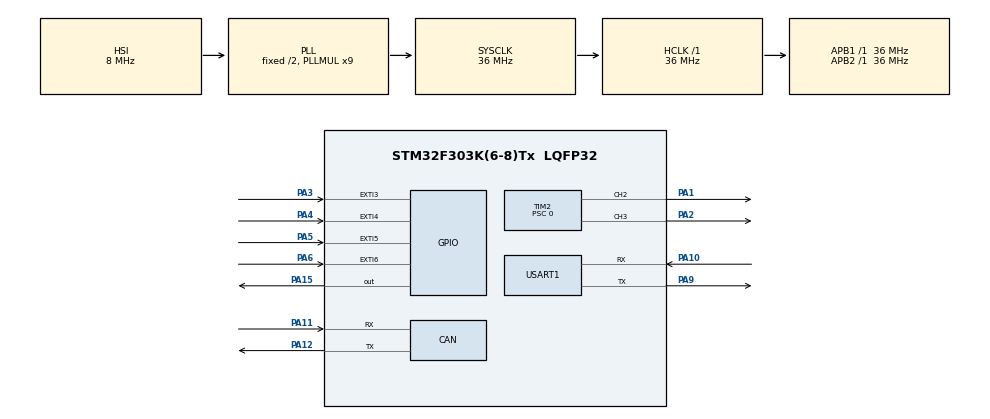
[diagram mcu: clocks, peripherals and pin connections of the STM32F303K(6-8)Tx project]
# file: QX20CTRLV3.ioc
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CAN.CalculateTimeQuantum=444.44444444444446
Dma.Request0=USART1_RX
Dma.Request1=USART1_TX
Dma.USART1_RX.0.Direction=DMA_PERIPH_TO_MEMORY
Dma.USART1_RX.0.Instance=DMA1_Channel5
Dma.USART1_RX.0.MemDataAlignment=DMA_MDATAALIGN_BYTE
Dma.USART1_RX.0.MemInc=DMA_MINC_ENABLE
Dma.USART1_RX.0.Mode=DMA_CIRCULAR
Dma.USART1_RX.0.PeriphDataAlignment=DMA_PDATAALIGN_BYTE
Dma.USART1_RX.0.PeriphInc=DMA_PINC_DISABLE
Dma.USART1_RX.0.Priority=DMA_PRIORITY_LOW
Dma.USART1_TX.1.Direction=DMA_MEMORY_TO_PERIPH
Dma.USART1_TX.1.Instance=DMA1_Channel4
Dma.USART1_TX.1.MemDataAlignment=DMA_MDATAALIGN_BYTE
Dma.USART1_TX.1.MemInc=DMA_MINC_ENABLE
Dma.USART1_TX.1.Mode=DMA_NORMAL
Dma.USART1_TX.1.PeriphDataAlignment=DMA_PDATAALIGN_BYTE
Dma.USART1_TX.1.PeriphInc=DMA_PINC_DISABLE
Dma.USART1_TX.1.Priority=DMA_PRIORITY_LOW
Mcu.Family=STM32F3
Mcu.Name=STM32F303K(6-8)Tx
Mcu.Package=LQFP32
NVIC.DMA1_Channel4_IRQn=true\:0\:0\:false\:false\:true\:false\:true
NVIC.DMA1_Channel5_IRQn=true\:0\:0\:false\:false\:true\:false\:true
NVIC.EXTI3_IRQn=true\:0\:0\:false\:false\:true\:true\:true
NVIC.EXTI4_IRQn=true\:0\:0\:false\:false\:true\:true\:true
NVIC.EXTI9_5_IRQn=true\:0\:0\:false\:false\:true\:true\:true
NVIC.PriorityGroup=NVIC_PRIORITYGROUP_4
PA1.Signal=S_TIM2_CH2
PA10.Mode=Asynchronous
PA10.Signal=USART1_RX
PA11.Mode=Master
PA11.Signal=CAN_RX
PA12.Mode=Master
PA12.Signal=CAN_TX
PA15.Signal=GPIO_Output
PA2.Signal=S_TIM2_CH3
PA3.GPIO_ModeDefaultEXTI=GPIO_MODE_IT_RISING_FALLING
PA3.GPIO_PuPd=GPIO_PULLUP
PA3.Signal=GPXTI3
PA4.GPIO_ModeDefaultEXTI=GPIO_MODE_IT_RISING_FALLING
PA4.GPIO_PuPd=GPIO_PULLUP
PA4.Signal=GPXTI4
PA5.GPIO_ModeDefaultEXTI=GPIO_MODE_IT_RISING_FALLING
PA5.GPIO_PuPd=GPIO_PULLUP
PA5.Signal=GPXTI5
PA6.GPIO_ModeDefaultEXTI=GPIO_MODE_IT_RISING_FALLING
PA6.GPIO_PuPd=GPIO_PULLUP
PA6.Signal=GPXTI6
PA9.Mode=Asynchronous
PA9.Signal=USART1_TX
ProjectManager.HeapSize=0x200
ProjectManager.StackSize=0x400
ProjectManager.TargetToolchain=Makefile
RCC.AHBFreq_Value=36000000
RCC.APB1Freq_Value=36000000
RCC.APB1TimFreq_Value=36000000
RCC.APB2Freq_Value=36000000
RCC.APB2TimFreq_Value=36000000
RCC.CortexFreq_Value=36000000
RCC.HCLKFreq_Value=36000000
RCC.HSE_VALUE=8000000
RCC.HSI_VALUE=8000000
RCC.PLLMUL=RCC_PLL_MUL9
RCC.SYSCLKFreq_VALUE=36000000
RCC.SYSCLKSourceVirtual=RCC_SYSCLKSOURCE_PLLCLK
SH.S_TIM2_CH2.0=TIM2_CH2,PWM Generation2 CH2
SH.S_TIM2_CH3.0=TIM2_CH3,PWM Generation3 CH3
TIM2.Channel-PWM\ Generation2\ CH2=TIM_CHANNEL_2
TIM2.Channel-PWM\ Generation3\ CH3=TIM_CHANNEL_3
TIM2.Period=720000
TIM2.Prescaler=0
TIM2.Pulse-PWM\ Generation2\ CH2=54000
TIM2.Pulse-PWM\ Generation3\ CH3=54000
USART1.VirtualMode-Asynchronous=VM_ASYNC
board=custom

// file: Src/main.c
/* USER CODE BEGIN Header */
/**
  ******************************************************************************
  * @file           : main.c
  * @brief          : Main program body
  ******************************************************************************
  * @attention
  *
  * <h2><center>&copy; Copyright (c) 2020 STMicroelectronics.
  * All rights reserved.</center></h2>
  *
  * This software component is licensed by ST under BSD 3-Clause license,
  * the "License"; You may not use this file except in compliance with the
  * License. You may obtain a copy of the License at:
  *                        opensource.org/licenses/BSD-3-Clause
  *
  ******************************************************************************
  */
/* USER CODE END Header */

#include "main.h"

/* USER CODE BEGIN Includes */
#include "qx20.h"
/* USER CODE END Includes */

CAN_HandleTypeDef hcan;

TIM_HandleTypeDef htim2;

UART_HandleTypeDef huart1;
DMA_HandleTypeDef hdma_usart1_rx;
DMA_HandleTypeDef hdma_usart1_tx;

void SystemClock_Config(void);
static void MX_GPIO_Init(void);
static void MX_DMA_Init(void);
static void MX_CAN_Init(void);
static void MX_TIM2_Init(void);
static void MX_USART1_UART_Init(void);

int main(void)
{

  /* MCU Configuration--------------------------------------------------------*/

  /* Reset of all peripherals, Initializes the Flash interface and the Systick. */
  HAL_Init();

  /* Configure the system clock */
  SystemClock_Config();

  /* Initialize all configured peripherals */
  MX_GPIO_Init();
  MX_DMA_Init();
  MX_CAN_Init();
  MX_TIM2_Init();
  MX_USART1_UART_Init();
  /* USER CODE BEGIN 2 */
	HAL_TIM_PWM_Start(&htim2, TIM_CHANNEL_2);
  HAL_TIM_PWM_Start(&htim2, TIM_CHANNEL_3);

  USART1_Init(&huart1);
  /* USER CODE END 2 */

  /* Infinite loop */
  while (1)
  {

  }
}

void SystemClock_Config(void)
{
  RCC_OscInitTypeDef RCC_OscInitStruct = {0};
  RCC_ClkInitTypeDef RCC_ClkInitStruct = {0};
  RCC_PeriphCLKInitTypeDef PeriphClkInit = {0};

  /** Initializes the CPU, AHB and APB busses clocks
  */
  RCC_OscInitStruct.OscillatorType = RCC_OSCILLATORTYPE_HSI;
  RCC_OscInitStruct.HSIState = RCC_HSI_ON;
  RCC_OscInitStruct.HSICalibrationValue = RCC_HSICALIBRATION_DEFAULT;
  RCC_OscInitStruct.PLL.PLLState = RCC_PLL_ON;
  RCC_OscInitStruct.PLL.PLLSource = RCC_PLLSOURCE_HSI;
  RCC_OscInitStruct.PLL.PLLMUL = RCC_PLL_MUL9;
  if (HAL_RCC_OscConfig(&RCC_OscInitStruct) != HAL_OK)
  {
    Error_Handler();
  }
  /** Initializes the CPU, AHB and APB busses clocks
  */
  RCC_ClkInitStruct.ClockType = RCC_CLOCKTYPE_HCLK|RCC_CLOCKTYPE_SYSCLK
                              |RCC_CLOCKTYPE_PCLK1|RCC_CLOCKTYPE_PCLK2;
  RCC_ClkInitStruct.SYSCLKSource = RCC_SYSCLKSOURCE_PLLCLK;
  RCC_ClkInitStruct.AHBCLKDivider = RCC_SYSCLK_DIV1;
  RCC_ClkInitStruct.APB1CLKDivider = RCC_HCLK_DIV1;
  RCC_ClkInitStruct.APB2CLKDivider = RCC_HCLK_DIV1;

  if (HAL_RCC_ClockConfig(&RCC_ClkInitStruct, FLASH_LATENCY_1) != HAL_OK)
  {
    Error_Handler();
  }
  PeriphClkInit.PeriphClockSelection = RCC_PERIPHCLK_USART1;
  PeriphClkInit.Usart1ClockSelection = RCC_USART1CLKSOURCE_PCLK1;
  if (HAL_RCCEx_PeriphCLKConfig(&PeriphClkInit) != HAL_OK)
  {
    Error_Handler();
  }
}

static void MX_CAN_Init(void)
{

  hcan.Instance = CAN;
  hcan.Init.Prescaler = 16;
  hcan.Init.Mode = CAN_MODE_NORMAL;
  hcan.Init.SyncJumpWidth = CAN_SJW_1TQ;
  hcan.Init.TimeSeg1 = CAN_BS1_1TQ;
  hcan.Init.TimeSeg2 = CAN_BS2_1TQ;
  hcan.Init.TimeTriggeredMode = DISABLE;
  hcan.Init.AutoBusOff = DISABLE;
  hcan.Init.AutoWakeUp = DISABLE;
  hcan.Init.AutoRetransmission = DISABLE;
  hcan.Init.ReceiveFifoLocked = DISABLE;
  hcan.Init.TransmitFifoPriority = DISABLE;
  if (HAL_CAN_Init(&hcan) != HAL_OK)
  {
    Error_Handler();
  }

}

static void MX_TIM2_Init(void)
{

  TIM_MasterConfigTypeDef sMasterConfig = {0};
  TIM_OC_InitTypeDef sConfigOC = {0};

  htim2.Instance = TIM2;
  htim2.Init.Prescaler = 0;
  htim2.Init.CounterMode = TIM_COUNTERMODE_UP;
  htim2.Init.Period = 720000;
  htim2.Init.ClockDivision = TIM_CLOCKDIVISION_DIV1;
  htim2.Init.AutoReloadPreload = TIM_AUTORELOAD_PRELOAD_DISABLE;
  if (HAL_TIM_PWM_Init(&htim2) != HAL_OK)
  {
    Error_Handler();
  }
  sMasterConfig.MasterOutputTrigger = TIM_TRGO_RESET;
  sMasterConfig.MasterSlaveMode = TIM_MASTERSLAVEMODE_DISABLE;
  if (HAL_TIMEx_MasterConfigSynchronization(&htim2, &sMasterConfig) != HAL_OK)
  {
    Error_Handler();
  }
  sConfigOC.OCMode = TIM_OCMODE_PWM1;
  sConfigOC.Pulse = 54000;
  sConfigOC.OCPolarity = TIM_OCPOLARITY_HIGH;
  sConfigOC.OCFastMode = TIM_OCFAST_DISABLE;
  if (HAL_TIM_PWM_ConfigChannel(&htim2, &sConfigOC, TIM_CHANNEL_2) != HAL_OK)
  {
    Error_Handler();
  }
  if (HAL_TIM_PWM_ConfigChannel(&htim2, &sConfigOC, TIM_CHANNEL_3) != HAL_OK)
  {
    Error_Handler();
  }
  HAL_TIM_MspPostInit(&htim2);

}

static void MX_USART1_UART_Init(void)
{

  huart1.Instance = USART1;
  huart1.Init.BaudRate = 38400;
  huart1.Init.WordLength = UART_WORDLENGTH_8B;
  huart1.Init.StopBits = UART_STOPBITS_1;
  huart1.Init.Parity = UART_PARITY_NONE;
  huart1.Init.Mode = UART_MODE_TX_RX;
  huart1.Init.HwFlowCtl = UART_HWCONTROL_NONE;
  huart1.Init.OverSampling = UART_OVERSAMPLING_16;
  huart1.Init.OneBitSampling = UART_ONE_BIT_SAMPLE_DISABLE;
  huart1.AdvancedInit.AdvFeatureInit = UART_ADVFEATURE_NO_INIT;
  if (HAL_UART_Init(&huart1) != HAL_OK)
  {
    Error_Handler();
  }

}

static void MX_DMA_Init(void)
{
  /* DMA controller clock enable */
  __HAL_RCC_DMA1_CLK_ENABLE();

  /* DMA interrupt init */
  /* DMA1_Channel4_IRQn interrupt configuration */
  HAL_NVIC_SetPriority(DMA1_Channel4_IRQn, 0, 0);
  HAL_NVIC_EnableIRQ(DMA1_Channel4_IRQn);
  /* DMA1_Channel5_IRQn interrupt configuration */
  HAL_NVIC_SetPriority(DMA1_Channel5_IRQn, 0, 0);
  HAL_NVIC_EnableIRQ(DMA1_Channel5_IRQn);

}

static void MX_GPIO_Init(void)
{
  GPIO_InitTypeDef GPIO_InitStruct = {0};

  /* GPIO Ports Clock Enable */
  __HAL_RCC_GPIOA_CLK_ENABLE();

  /*Configure GPIO pin Output Level */
  HAL_GPIO_WritePin(GPIOA, GPIO_PIN_15, GPIO_PIN_RESET);

  /*Configure GPIO pins : PA3 PA4 PA5 PA6 */
  GPIO_InitStruct.Pin = GPIO_PIN_3|GPIO_PIN_4|GPIO_PIN_5|GPIO_PIN_6;
  GPIO_InitStruct.Mode = GPIO_MODE_IT_RISING_FALLING;
  GPIO_InitStruct.Pull = GPIO_PULLUP;
  HAL_GPIO_Init(GPIOA, &GPIO_InitStruct);

  /*Configure GPIO pin : PA15 */
  GPIO_InitStruct.Pin = GPIO_PIN_15;
  GPIO_InitStruct.Mode = GPIO_MODE_OUTPUT_PP;
  GPIO_InitStruct.Pull = GPIO_NOPULL;
  GPIO_InitStruct.Speed = GPIO_SPEED_FREQ_LOW;
  HAL_GPIO_Init(GPIOA, &GPIO_InitStruct);

  /* EXTI interrupt init*/
  HAL_NVIC_SetPriority(EXTI3_IRQn, 0, 0);
  HAL_NVIC_EnableIRQ(EXTI3_IRQn);

  HAL_NVIC_SetPriority(EXTI4_IRQn, 0, 0);
  HAL_NVIC_EnableIRQ(EXTI4_IRQn);

  HAL_NVIC_SetPriority(EXTI9_5_IRQn, 0, 0);
  HAL_NVIC_EnableIRQ(EXTI9_5_IRQn);

}

void Error_Handler(void)
{
}

/************************ (C) COPYRIGHT STMicroelectronics *****END OF FILE****/
